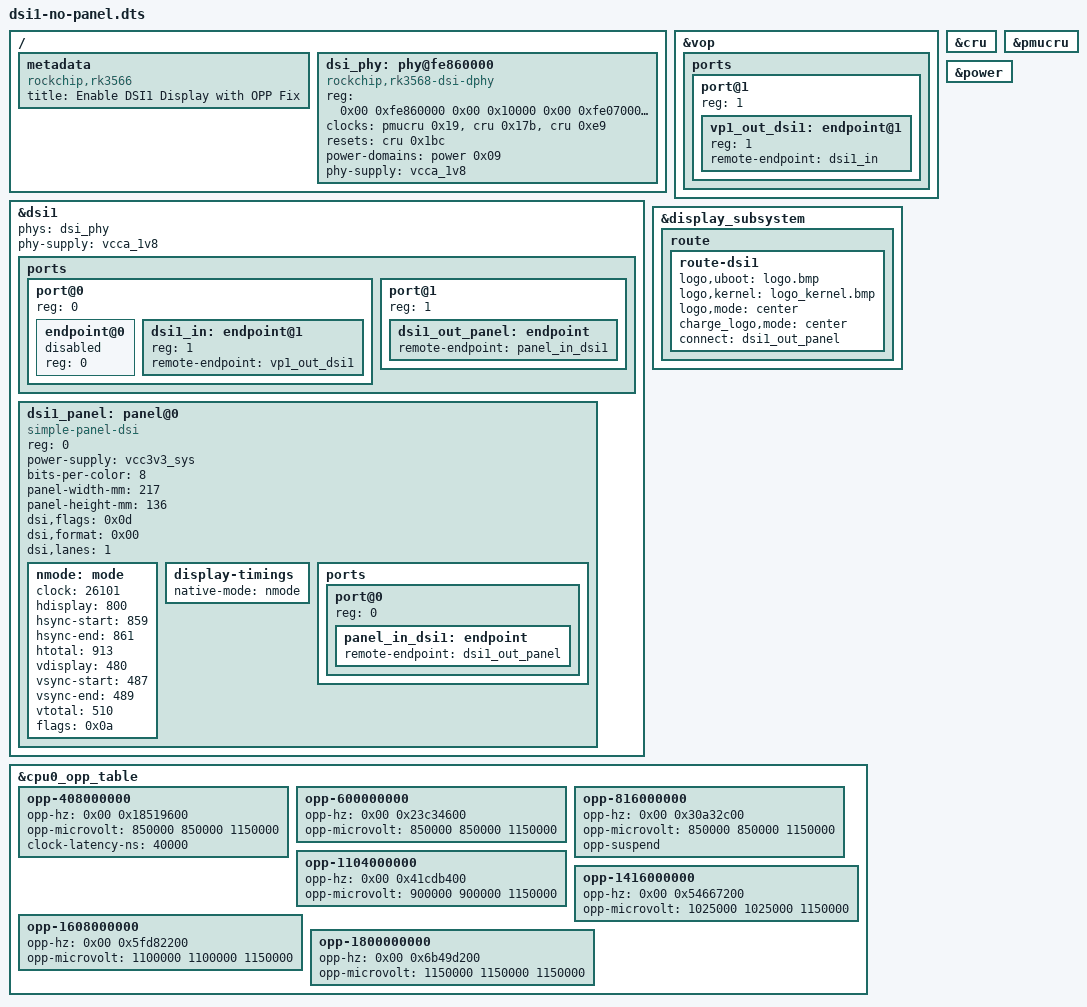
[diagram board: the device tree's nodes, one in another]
/dts-v1/;
/plugin/;

/ {
	metadata {
		title = "Enable DSI1 Display with OPP Fix";
		compatible = "rockchip,rk3566";
	};

	fragment@0 {
		target = <&dsi1>;
		__overlay__ {
			status = "okay";
			#address-cells = <1>;
			#size-cells = <0>;

			phys = <&dsi_phy>; /* Reference phy@fe860000 */
			phy-names = "dphy";
			phy-supply = <&vcca_1v8>; /* Assuming <0x62> is vcc3v3_sys from dt-mainline.dts */

			ports {
				#address-cells = <1>;
				#size-cells = <0>;

				port@0 {
					reg = <0>;

					endpoint@0 {
						reg = <0>;
						status = "disabled";
					};

					dsi1_in: endpoint@1 {
						reg = <1>;
						status = "okay";
						remote-endpoint = <&vp1_out_dsi1>;
					};
				};

				port@1 {
					reg = <1>;
					dsi1_out_panel: endpoint {
						remote-endpoint = <&panel_in_dsi1>;
					};
				};
			};

			dsi1_panel: panel@0 {
				status = "okay";
				compatible = "simple-panel-dsi";
				reg = <0>;
				power-supply = <&vcc3v3_sys>; /* Assuming <0x3f> is vcc3v3_sys */

				bits-per-color = <8>;
				panel-width-mm = <217>;
				panel-height-mm = <136>;

				dsi,flags = <0x0d>; /* MIPI_DSI_MODE_VIDEO | MIPI_DSI_MODE_VIDEO_BURST | MIPI_DSI_MODE_LPM */
				dsi,format = <0x00>; /* MIPI_DSI_FMT_RGB888 */
				dsi,lanes = <1>;

				/* From panel-simple.c */
				nmode: mode {
					clock = <26101>; /* kHz */
					hdisplay = <800>;
					hsync-start = <859>;
					hsync-end = <861>;
					htotal = <913>;
					vdisplay = <480>;
					vsync-start = <487>;
					vsync-end = <489>;
					vtotal = <510>;
					flags = <0x0a>; /* DRM_MODE_FLAG_NVSYNC | DRM_MODE_FLAG_NHSYNC */
				};

				display-timings {
					native-mode = <&nmode>;
				};

				ports {
					#address-cells = <1>;
					#size-cells = <0>;
					port@0 {
						reg = <0>;
						panel_in_dsi1: endpoint {
							remote-endpoint = <&dsi1_out_panel>;
						};
					};
				};
			};
		};
	};

	/* Fragment 1: Configure VOP vp1 output */
	fragment@1 {
		target = <&vop>;
		__overlay__ {
			ports {
				#address-cells = <1>;
				#size-cells = <0>;
				port@1 {  /* vp1 for DSI1 */
					reg = <1>;

					vp1_out_dsi1: endpoint@1 {
						reg = <1>;
						remote-endpoint = <&dsi1_in>;
					};
				};
			};
		};
	};

	/* Fragment 3: Add route-dsi1 to display-subsystem */
	fragment@3 {
		target = <&display_subsystem>;
		__overlay__ {
			route {
				route-dsi1 {
					status = "okay";
					logo,uboot = "logo.bmp";
					logo,kernel = "logo_kernel.bmp";
					logo,mode = "center";
					charge_logo,mode = "center";
					connect = <&dsi1_out_panel>;
				};
			};
		};
	};

	/* Fragment 4: Fix OPP table */
	fragment@4 {
		target = <&cpu0_opp_table>;
		__overlay__ {
			opp-408000000 {
				opp-hz = <0x00 0x18519600>;
				opp-microvolt = <850000 850000 1150000>;
				clock-latency-ns = <40000>;
			};
			opp-600000000 {
				opp-hz = <0x00 0x23c34600>;
				opp-microvolt = <850000 850000 1150000>;
			};
			opp-816000000 {
				opp-hz = <0x00 0x30a32c00>;
				opp-microvolt = <850000 850000 1150000>;
				opp-suspend;
			};
			opp-1104000000 {
				opp-hz = <0x00 0x41cdb400>;
				opp-microvolt = <900000 900000 1150000>;
			};
			opp-1416000000 {
				opp-hz = <0x00 0x54667200>;
				opp-microvolt = <1025000 1025000 1150000>;
			};
			opp-1608000000 {
				opp-hz = <0x00 0x5fd82200>;
				opp-microvolt = <1100000 1100000 1150000>;
			};
			opp-1800000000 {
				opp-hz = <0x00 0x6b49d200>;
				opp-microvolt = <1150000 1150000 1150000>; /* Increase to avoid 1.05V */
			};
		};
	};

	/* Fragment 5: Ensure clock controllers are enabled */
	fragment@5 {
		target = <&cru>;
		__overlay__ {
			status = "okay";
		};
	};

	fragment@6 {
		target = <&pmucru>;
		__overlay__ {
			status = "okay";
		};
	};

	/* Fragment 7: Ensure power domain controller is enabled */
	fragment@7 {
		target = <&power>;
		__overlay__ {
			status = "okay";
		};
	};

	fragment@8 {
		target-path = "/";
		__overlay__ {
			dsi_phy: phy@fe860000 {
				compatible = "rockchip,rk3568-dsi-dphy", "rockchip,rk3568-video-phy";
				reg = <0x00 0xfe860000 0x00 0x10000 0x00 0xfe070000 0x00 0x10000>;
				reg-names = "phy", "host";
				clocks = <&pmucru 0x19>, <&cru 0x17b>, <&cru 0xe9>;
				clock-names = "ref", "pclk", "pclk_host";
				resets = <&cru 0x1bc>;
				reset-names = "apb";
				power-domains = <&power 0x09>; /* PD_VOP1 */
				#phy-cells = <0>;
				status = "okay";
				phy-supply = <&vcca_1v8>; /* Match <0x62> */
			};
		};
	};
};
